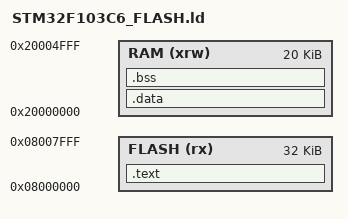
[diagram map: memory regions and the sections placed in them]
/* Flash and SRAM sizes for STM32F103C6 */
MEMORY
{
  FLASH (rx) : ORIGIN = 0x08000000, LENGTH = 32K
  RAM (xrw)  : ORIGIN = 0x20000000, LENGTH = 20K
}

ENTRY(Reset_Handler)

SECTIONS
{
  .text :
  {
    KEEP(*(.isr_vector))
    *(.text*)
    *(.rodata*)
    _etext = .;
  } > FLASH

  .data : AT(_etext)
  {
    _sdata = .;
    *(.data*)
    _edata = .;
  } > RAM

  .bss :
  {
    _sbss = .;
    *(.bss*)
    *(COMMON)
    _ebss = .;
  } > RAM
}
